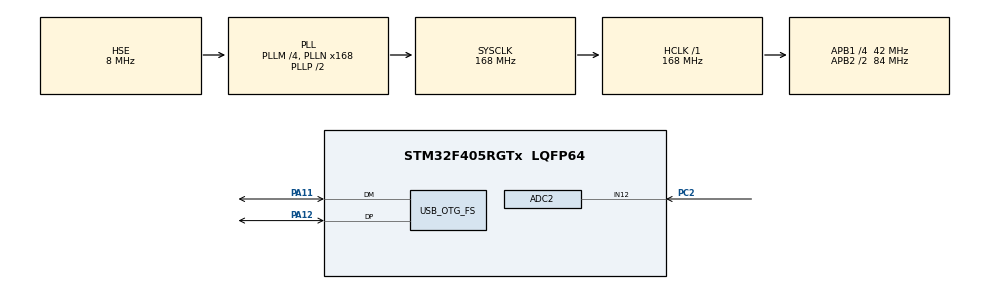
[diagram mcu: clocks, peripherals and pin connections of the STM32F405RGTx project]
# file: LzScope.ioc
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ADC1.Channel-24\#ChannelRegularConversion=ADC_CHANNEL_VREFINT
ADC1.ClockPrescaler=ADC_CLOCK_SYNC_PCLK_DIV4
ADC1.ContinuousConvMode=ENABLE
ADC1.DMAContinuousRequests=ENABLE
ADC1.DataAlign=ADC_DATAALIGN_RIGHT
ADC1.DiscontinuousConvMode=DISABLE
ADC1.EOCSelection=ADC_EOC_SINGLE_CONV
ADC1.EnableAnalogWatchDog=false
ADC1.ExternalTrigConv=ADC_SOFTWARE_START
ADC1.ExternalTrigConvEdge=ADC_EXTERNALTRIGCONVEDGE_NONE
ADC1.InjNumberOfConversion=0
ADC1.NbrOfConversion=1
ADC1.NbrOfConversionFlag=1
ADC1.Rank-24\#ChannelRegularConversion=1
ADC1.Resolution=ADC_RESOLUTION_12B
ADC1.SamplingTime-24\#ChannelRegularConversion=ADC_SAMPLETIME_3CYCLES
ADC1.ScanConvMode=DISABLE
ADC1.master=1
ADC2.Channel-4\#ChannelRegularConversion=ADC_CHANNEL_12
ADC2.ClockPrescaler=ADC_CLOCK_SYNC_PCLK_DIV4
ADC2.ContinuousConvMode=ENABLE
ADC2.DMAContinuousRequests=ENABLE
ADC2.DataAlign=ADC_DATAALIGN_RIGHT
ADC2.DiscontinuousConvMode=DISABLE
ADC2.EOCSelection=ADC_EOC_SINGLE_CONV
ADC2.EnableAnalogWatchDog=false
ADC2.ExternalTrigConv=ADC_SOFTWARE_START
ADC2.ExternalTrigConvEdge=ADC_EXTERNALTRIGCONVEDGE_NONE
ADC2.InjNumberOfConversion=0
ADC2.NbrOfConversion=1
ADC2.NbrOfConversionFlag=1
ADC2.Rank-4\#ChannelRegularConversion=1
ADC2.Resolution=ADC_RESOLUTION_12B
ADC2.SamplingTime-4\#ChannelRegularConversion=ADC_SAMPLETIME_3CYCLES
ADC2.ScanConvMode=DISABLE
Dma.ADC1.0.Direction=DMA_PERIPH_TO_MEMORY
Dma.ADC1.0.FIFOMode=DMA_FIFOMODE_ENABLE
Dma.ADC1.0.FIFOThreshold=DMA_FIFO_THRESHOLD_HALFFULL
Dma.ADC1.0.Instance=DMA2_Stream0
Dma.ADC1.0.MemBurst=DMA_MBURST_SINGLE
Dma.ADC1.0.MemDataAlignment=DMA_MDATAALIGN_HALFWORD
Dma.ADC1.0.MemInc=DMA_MINC_ENABLE
Dma.ADC1.0.Mode=DMA_CIRCULAR
Dma.ADC1.0.PeriphBurst=DMA_PBURST_SINGLE
Dma.ADC1.0.PeriphDataAlignment=DMA_PDATAALIGN_HALFWORD
Dma.ADC1.0.PeriphInc=DMA_PINC_DISABLE
Dma.ADC1.0.Priority=DMA_PRIORITY_MEDIUM
Dma.ADC2.1.Direction=DMA_PERIPH_TO_MEMORY
Dma.ADC2.1.FIFOMode=DMA_FIFOMODE_ENABLE
Dma.ADC2.1.FIFOThreshold=DMA_FIFO_THRESHOLD_HALFFULL
Dma.ADC2.1.Instance=DMA2_Stream2
Dma.ADC2.1.MemBurst=DMA_MBURST_SINGLE
Dma.ADC2.1.MemDataAlignment=DMA_MDATAALIGN_HALFWORD
Dma.ADC2.1.MemInc=DMA_MINC_ENABLE
Dma.ADC2.1.Mode=DMA_CIRCULAR
Dma.ADC2.1.PeriphBurst=DMA_PBURST_SINGLE
Dma.ADC2.1.PeriphDataAlignment=DMA_PDATAALIGN_HALFWORD
Dma.ADC2.1.PeriphInc=DMA_PINC_DISABLE
Dma.ADC2.1.Priority=DMA_PRIORITY_MEDIUM
Dma.Request0=ADC1
Dma.Request1=ADC2
Mcu.Family=STM32F4
Mcu.Name=STM32F405RGTx
Mcu.Package=LQFP64
NVIC.DMA2_Stream0_IRQn=true\:0\:0\:false\:false\:true
NVIC.DMA2_Stream2_IRQn=true\:0\:0\:false\:false\:true
NVIC.OTG_FS_IRQn=true\:0\:0\:false\:false\:true
NVIC.PriorityGroup=NVIC_PRIORITYGROUP_4
PA11.Mode=Device_Only
PA11.Signal=USB_OTG_FS_DM
PA12.Mode=Device_Only
PA12.Signal=USB_OTG_FS_DP
PC2.Signal=ADCx_IN12
PH0-OSC_IN.Mode=HSE-External-Oscillator
PH0-OSC_IN.Signal=RCC_OSC_IN
PH1-OSC_OUT.Mode=HSE-External-Oscillator
PH1-OSC_OUT.Signal=RCC_OSC_OUT
ProjectManager.HeapSize=0x200
ProjectManager.StackSize=0x400
ProjectManager.TargetToolchain=Makefile
RCC.48MHZClocksFreq_Value=48000000
RCC.AHBFreq_Value=168000000
RCC.APB1CLKDivider=RCC_HCLK_DIV4
RCC.APB1Freq_Value=42000000
RCC.APB1TimFreq_Value=84000000
RCC.APB2CLKDivider=RCC_HCLK_DIV2
RCC.APB2Freq_Value=84000000
RCC.APB2TimFreq_Value=168000000
RCC.CortexFreq_Value=168000000
RCC.HCLKFreq_Value=168000000
RCC.HSE_VALUE=8000000
RCC.HSI_VALUE=16000000
RCC.LSE_VALUE=32768
RCC.PLLM=4
RCC.PLLN=168
RCC.PLLQ=7
RCC.SYSCLKFreq_VALUE=168000000
RCC.SYSCLKSource=RCC_SYSCLKSOURCE_PLLCLK
RCC.VCOOutputFreq_Value=336000000
SH.ADCx_IN12.0=ADC2_IN12,IN12
USB_DEVICE.CLASS_NAME_FS=CDC
USB_DEVICE.MANUFACTURER_STRING-CDC_FS=Evgeny P. Kurbatov
USB_DEVICE.PRODUCT_STRING_CDC_FS=LzScope
USB_DEVICE.VirtualModeFS=Cdc_FS
USB_OTG_FS.VirtualMode=Device_Only
VP_ADC1_Vref_Input.Mode=IN-Vrefint
VP_USB_DEVICE_VS_USB_DEVICE_CDC_FS.Mode=CDC_FS
board=LzScope

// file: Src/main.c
/**
  ******************************************************************************
  * File Name          : main.c
  * Description        : Main program body
  ******************************************************************************
  * This notice applies to any and all portions of this file
  * that are not between comment pairs USER CODE BEGIN and
  * USER CODE END. Other portions of this file, whether
  * inserted by the user or by software development tools
  * are owned by their respective copyright owners.
  *
  * Copyright (c) 2018 STMicroelectronics International N.V.
  * All rights reserved.
  *
  * Redistribution and use in source and binary forms, with or without
  * modification, are permitted, provided that the following conditions are met:
  *
  * 1. Redistribution of source code must retain the above copyright notice,
  *    this list of conditions and the following disclaimer.
  * 2. Redistributions in binary form must reproduce the above copyright notice,
  *    this list of conditions and the following disclaimer in the documentation
  *    and/or other materials provided with the distribution.
  * 3. Neither the name of STMicroelectronics nor the names of other
  *    contributors to this software may be used to endorse or promote products
  *    derived from this software without specific written permission.
  * 4. This software, including modifications and/or derivative works of this
  *    software, must execute solely and exclusively on microcontroller or
  *    microprocessor devices manufactured by or for STMicroelectronics.
  * 5. Redistribution and use of this software other than as permitted under
  *    this license is void and will automatically terminate your rights under
  *    this license.
  *
  * THIS SOFTWARE IS PROVIDED BY STMICROELECTRONICS AND CONTRIBUTORS "AS IS"
  * AND ANY EXPRESS, IMPLIED OR STATUTORY WARRANTIES, INCLUDING, BUT NOT
  * LIMITED TO, THE IMPLIED WARRANTIES OF MERCHANTABILITY, FITNESS FOR A
  * PARTICULAR PURPOSE AND NON-INFRINGEMENT OF THIRD PARTY INTELLECTUAL PROPERTY
  * RIGHTS ARE DISCLAIMED TO THE FULLEST EXTENT PERMITTED BY LAW. IN NO EVENT
  * SHALL STMICROELECTRONICS OR CONTRIBUTORS BE LIABLE FOR ANY DIRECT, INDIRECT,
  * INCIDENTAL, SPECIAL, EXEMPLARY, OR CONSEQUENTIAL DAMAGES (INCLUDING, BUT NOT
  * LIMITED TO, PROCUREMENT OF SUBSTITUTE GOODS OR SERVICES; LOSS OF USE, DATA,
  * OR PROFITS; OR BUSINESS INTERRUPTION) HOWEVER CAUSED AND ON ANY THEORY OF
  * LIABILITY, WHETHER IN CONTRACT, STRICT LIABILITY, OR TORT (INCLUDING
  * NEGLIGENCE OR OTHERWISE) ARISING IN ANY WAY OUT OF THE USE OF THIS SOFTWARE,
  * EVEN IF ADVISED OF THE POSSIBILITY OF SUCH DAMAGE.
  *
  ******************************************************************************
  */
#include "main.h"
#include "stm32f4xx_hal.h"
#include "adc.h"
#include "dma.h"
#include "usb_device.h"
#include "gpio.h"

/* USER CODE BEGIN Includes */

#include "usbd_cdc_if.h"
#include "adc.h"
//#include "stm32f4xx_ll_usb.h"
#include "ringbuffer.h"
#include "workers.h"

/* USER CODE END Includes */

/* USER CODE BEGIN PV */
/* Private variables ---------------------------------------------------------*/

GPIO_InitTypeDef GPIO_InitStruct;

extern RingBufferTypeDef RxRingBuffer;

/* USER CODE END PV */

void SystemClock_Config(void);

/* USER CODE BEGIN PFP */
/* Private function prototypes -----------------------------------------------*/

/* USER CODE END PFP */

int main(void)
{

  /* MCU Configuration----------------------------------------------------------*/

  /* Reset of all peripherals, Initializes the Flash interface and the Systick. */
  HAL_Init();

  /* Configure the system clock */
  SystemClock_Config();

  /* Initialize all configured peripherals */
  MX_GPIO_Init();
  MX_DMA_Init();
  MX_USB_DEVICE_Init();
  MX_ADC1_Init();
  MX_ADC2_Init();

  /* USER CODE BEGIN 2 */

  /* Initialize a BUSY led. */
  GPIO_InitStruct.Pin = GPIO_PIN_7;
  GPIO_InitStruct.Mode = GPIO_MODE_OUTPUT_PP;
  GPIO_InitStruct.Pull = GPIO_NOPULL;
  GPIO_InitStruct.Speed = GPIO_SPEED_FREQ_LOW;
  HAL_GPIO_Init(GPIOB, &GPIO_InitStruct);
  HAL_GPIO_WritePin(GPIOB, GPIO_PIN_7, GPIO_PIN_RESET);

  /* USER CODE END 2 */

  /* Infinite loop */
  while (1)
  {

  /* USER CODE BEGIN 3 */

    if (RingBuffer_IsEmpty(&RxRingBuffer) == false)
    {
      /*
       * Parse command
       */

      char CmdBuffer[RX_RING_BUFFER_DATA_SIZE];
      for (uint32_t i=0; i < RxRingBuffer.Length; i++)
      {
        CmdBuffer[i] = RingBuffer_Remove(&RxRingBuffer);
        if (CmdBuffer[i] == '\0')
          break;
      }

      #define TOKEN_SIZE 16
      char CmdName[TOKEN_SIZE] = "";
      char CmdArg1[TOKEN_SIZE] = "";
      int res = sscanf(CmdBuffer, "%s %s", CmdName, CmdArg1);

      /*
       * Execute command
       */

      if (!strcasecmp(CmdName, "RESET"))
      {
        Transmit("OK", 3);
        continue;
      }
      if (!strcasecmp(CmdName, "ADC1"))
      {
        Worker_ExecuteCommand_ADC(&hadc1);
        continue;
      }
      if (!strcasecmp(CmdName, "ADC2"))
      {
        Worker_ExecuteCommand_ADC(&hadc2);
        continue;
      }
      if (!strcasecmp(CmdName, "ADC1DMA"))
      {
        Worker_ExecuteCommand_ADCDMA(&hadc1, CmdArg1);
        continue;
      }
      if (!strcasecmp(CmdName, "ADC2DMA"))
      {
        Worker_ExecuteCommand_ADCDMA(&hadc2, CmdArg1);
        continue;
      }

    }
  }
  /* USER CODE END 3 */

}

/** System Clock Configuration
*/
void SystemClock_Config(void)
{

  RCC_OscInitTypeDef RCC_OscInitStruct;
  RCC_ClkInitTypeDef RCC_ClkInitStruct;

    /**Configure the main internal regulator output voltage
    */
  __HAL_RCC_PWR_CLK_ENABLE();

  __HAL_PWR_VOLTAGESCALING_CONFIG(PWR_REGULATOR_VOLTAGE_SCALE1);

    /**Initializes the CPU, AHB and APB busses clocks
    */
  RCC_OscInitStruct.OscillatorType = RCC_OSCILLATORTYPE_HSE;
  RCC_OscInitStruct.HSEState = RCC_HSE_ON;
  RCC_OscInitStruct.PLL.PLLState = RCC_PLL_ON;
  RCC_OscInitStruct.PLL.PLLSource = RCC_PLLSOURCE_HSE;
  RCC_OscInitStruct.PLL.PLLM = 4;
  RCC_OscInitStruct.PLL.PLLN = 168;
  RCC_OscInitStruct.PLL.PLLP = RCC_PLLP_DIV2;
  RCC_OscInitStruct.PLL.PLLQ = 7;
  if (HAL_RCC_OscConfig(&RCC_OscInitStruct) != HAL_OK)
  {
    _Error_Handler(__FILE__, __LINE__);
  }

    /**Initializes the CPU, AHB and APB busses clocks
    */
  RCC_ClkInitStruct.ClockType = RCC_CLOCKTYPE_HCLK|RCC_CLOCKTYPE_SYSCLK
                              |RCC_CLOCKTYPE_PCLK1|RCC_CLOCKTYPE_PCLK2;
  RCC_ClkInitStruct.SYSCLKSource = RCC_SYSCLKSOURCE_PLLCLK;
  RCC_ClkInitStruct.AHBCLKDivider = RCC_SYSCLK_DIV1;
  RCC_ClkInitStruct.APB1CLKDivider = RCC_HCLK_DIV4;
  RCC_ClkInitStruct.APB2CLKDivider = RCC_HCLK_DIV2;

  if (HAL_RCC_ClockConfig(&RCC_ClkInitStruct, FLASH_LATENCY_5) != HAL_OK)
  {
    _Error_Handler(__FILE__, __LINE__);
  }

    /**Configure the Systick interrupt time
    */
  HAL_SYSTICK_Config(HAL_RCC_GetHCLKFreq()/1000);

    /**Configure the Systick
    */
  HAL_SYSTICK_CLKSourceConfig(SYSTICK_CLKSOURCE_HCLK);

  /* SysTick_IRQn interrupt configuration */
  HAL_NVIC_SetPriority(SysTick_IRQn, 0, 0);
}

void _Error_Handler(char * file, int line)
{
  while(1)
  {
  }
}

/************************ (C) COPYRIGHT STMicroelectronics *****END OF FILE****/
